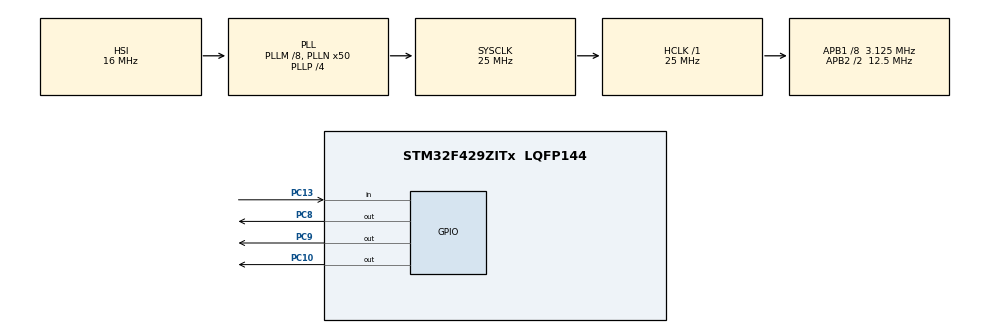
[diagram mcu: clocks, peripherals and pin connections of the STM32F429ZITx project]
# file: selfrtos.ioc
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FREERTOS.BinarySemaphores01=myBinarySem01,Dynamic,NULL
FREERTOS.Tasks01=defaultTask,0,128,StartDefaultTask,Default,NULL,Dynamic,NULL,NULL;shayantask,-3,128,startshayntask,Default,NULL,Dynamic,NULL,NULL
Mcu.Family=STM32F4
Mcu.Name=STM32F429ZITx
Mcu.Package=LQFP144
NVIC.PriorityGroup=NVIC_PRIORITYGROUP_4
NVIC.RCC_IRQn=true\:5\:0\:false\:false\:true\:true\:true
NVIC.TIM6_DAC_IRQn=true\:0\:0\:false\:false\:true\:false\:false
NVIC.TimeBase=TIM6_DAC_IRQn
NVIC.TimeBaseIP=TIM6
PC10.Signal=GPIO_Output
PC13.Signal=GPIO_Input
PC8.Signal=GPIO_Output
PC9.Signal=GPIO_Output
ProjectManager.HeapSize=0x200
ProjectManager.StackSize=0x400
ProjectManager.TargetToolchain=SW4STM32
RCC.48MHZClocksFreq_Value=14285714.285714285
RCC.AHBFreq_Value=25000000
RCC.APB1CLKDivider=RCC_HCLK_DIV8
RCC.APB1Freq_Value=3125000
RCC.APB1TimFreq_Value=6250000
RCC.APB2CLKDivider=RCC_HCLK_DIV2
RCC.APB2Freq_Value=12500000
RCC.APB2TimCLKDivider=1
RCC.APB2TimFreq_Value=12500000
RCC.CortexFreq_Value=25000000
RCC.HCLKFreq_Value=25000000
RCC.HSE_VALUE=8000000
RCC.HSI_VALUE=16000000
RCC.LSE_VALUE=32768
RCC.PLLM=8
RCC.PLLMUL=RCC_PLL_MUL9
RCC.PLLN=50
RCC.PLLP=RCC_PLLP_DIV4
RCC.PLLQ=7
RCC.PRESCALERUSB=RCC_USBCLKSOURCE_PLL_DIV1_5
RCC.SYSCLKFreq_VALUE=25000000
RCC.SYSCLKSource=RCC_SYSCLKSOURCE_PLLCLK
RCC.SYSCLKSourceVirtual=RCC_SYSCLKSOURCE_PLLCLK
RCC.USBFreq_Value=48000000
RCC.VCOOutputFreq_Value=100000000
VP_FREERTOS_VS_ENABLE.Mode=Enabled
VP_SYS_VS_tim6.Mode=TIM6
board=NUCLEO-F429ZI

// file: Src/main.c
/**
  ******************************************************************************
  * @file           : main.c
  * @brief          : Main program body
  ******************************************************************************
  * This notice applies to any and all portions of this file
  * that are not between comment pairs USER CODE BEGIN and
  * USER CODE END. Other portions of this file, whether
  * inserted by the user or by software development tools
  * are owned by their respective copyright owners.
  *
  * Copyright (c) 2019 STMicroelectronics International N.V.
  * All rights reserved.
  *
  * Redistribution and use in source and binary forms, with or without
  * modification, are permitted, provided that the following conditions are met:
  *
  * 1. Redistribution of source code must retain the above copyright notice,
  *    this list of conditions and the following disclaimer.
  * 2. Redistributions in binary form must reproduce the above copyright notice,
  *    this list of conditions and the following disclaimer in the documentation
  *    and/or other materials provided with the distribution.
  * 3. Neither the name of STMicroelectronics nor the names of other
  *    contributors to this software may be used to endorse or promote products
  *    derived from this software without specific written permission.
  * 4. This software, including modifications and/or derivative works of this
  *    software, must execute solely and exclusively on microcontroller or
  *    microprocessor devices manufactured by or for STMicroelectronics.
  * 5. Redistribution and use of this software other than as permitted under
  *    this license is void and will automatically terminate your rights under
  *    this license.
  *
  * THIS SOFTWARE IS PROVIDED BY STMICROELECTRONICS AND CONTRIBUTORS "AS IS"
  * AND ANY EXPRESS, IMPLIED OR STATUTORY WARRANTIES, INCLUDING, BUT NOT
  * LIMITED TO, THE IMPLIED WARRANTIES OF MERCHANTABILITY, FITNESS FOR A
  * PARTICULAR PURPOSE AND NON-INFRINGEMENT OF THIRD PARTY INTELLECTUAL PROPERTY
  * RIGHTS ARE DISCLAIMED TO THE FULLEST EXTENT PERMITTED BY LAW. IN NO EVENT
  * SHALL STMICROELECTRONICS OR CONTRIBUTORS BE LIABLE FOR ANY DIRECT, INDIRECT,
  * INCIDENTAL, SPECIAL, EXEMPLARY, OR CONSEQUENTIAL DAMAGES (INCLUDING, BUT NOT
  * LIMITED TO, PROCUREMENT OF SUBSTITUTE GOODS OR SERVICES; LOSS OF USE, DATA,
  * OR PROFITS; OR BUSINESS INTERRUPTION) HOWEVER CAUSED AND ON ANY THEORY OF
  * LIABILITY, WHETHER IN CONTRACT, STRICT LIABILITY, OR TORT (INCLUDING
  * NEGLIGENCE OR OTHERWISE) ARISING IN ANY WAY OUT OF THE USE OF THIS SOFTWARE,
  * EVEN IF ADVISED OF THE POSSIBILITY OF SUCH DAMAGE.
  *
  ******************************************************************************
  */
#include "main.h"
#include "stm32f4xx_hal.h"
#include "cmsis_os.h"
#include "UARTinit.h"

osThreadId defaultTaskHandle;
osThreadId shayantaskHandle;
osSemaphoreId myBinarySem01Handle;

/* USER CODE BEGIN PV */
/* Private variables ---------------------------------------------------------*/

/* USER CODE END PV */

void SystemClock_Config(void);
static void MX_GPIO_Init(void);
void StartDefaultTask(void const * argument);
void startshayntask(void const * argument);
//void Setuart(UART_HandleTypeDef *huart);
/* USER CODE BEGIN PFP */
/* Private function prototypes -----------------------------------------------*/

/* USER CODE END PFP */

/* USER CODE BEGIN 0 */

/* UART handler declaration */
UART_HandleTypeDef UartHandle;
uint8_t mydata[13] = "sosyanworld\r\n";

/* USER CODE END 0 */

int main(void)
{

  /* MCU Configuration----------------------------------------------------------*/

  /* Reset of all peripherals, Initializes the Flash interface and the Systick. */
  HAL_Init();

  /* Configure the system clock */
  SystemClock_Config();

  /* Initialize all configured peripherals */
  MX_GPIO_Init();
  /* USER CODE BEGIN 2 */
  Setuart(&UartHandle);

  /*
	  __HAL_RCC_USART3_CLK_ENABLE();

	  UartHandle.Instance        = USARTx;
	  UartHandle.Init.BaudRate   = 9600;
	  UartHandle.Init.WordLength = UART_WORDLENGTH_8B;
	  UartHandle.Init.StopBits   = UART_STOPBITS_1;
	  UartHandle.Init.Parity     = UART_PARITY_ODD;
	  UartHandle.Init.HwFlowCtl  = UART_HWCONTROL_NONE;
	  UartHandle.Init.Mode       = UART_MODE_TX_RX;
	  UartHandle.Init.OverSampling = UART_OVERSAMPLING_16;

	  */

  if (HAL_UART_Init(&UartHandle) != HAL_OK)
  {
    /* Initialization Error */
    Error_Handler();
  }
  /* Output a message on Hyperterminal using printf function */
  	    HAL_UART_Transmit(&UartHandle,mydata,13,10);
  /* USER CODE END 2 */

  /* Create the semaphores(s) */
  /* definition and creation of myBinarySem01 */
  osSemaphoreDef(myBinarySem01);
  myBinarySem01Handle = osSemaphoreCreate(osSemaphore(myBinarySem01), 1);

  /* Create the thread(s) */
  /* definition and creation of defaultTask */
  osThreadDef(defaultTask, StartDefaultTask, osPriorityNormal, 0, 128);
  defaultTaskHandle = osThreadCreate(osThread(defaultTask), NULL);

  /* definition and creation of shayantask */
  osThreadDef(shayantask, startshayntask, osPriorityIdle, 0, 128);
  shayantaskHandle = osThreadCreate(osThread(shayantask), NULL);

  /* Start scheduler */
  osKernelStart();

  /* We should never get here as control is now taken by the scheduler */

  /* Infinite loop */
  while (1)
  {

  }

}

void SystemClock_Config(void)
{

  RCC_OscInitTypeDef RCC_OscInitStruct;
  RCC_ClkInitTypeDef RCC_ClkInitStruct;

    /**Configure the main internal regulator output voltage
    */
  __HAL_RCC_PWR_CLK_ENABLE();

  __HAL_PWR_VOLTAGESCALING_CONFIG(PWR_REGULATOR_VOLTAGE_SCALE3);

    /**Initializes the CPU, AHB and APB busses clocks
    */
  RCC_OscInitStruct.OscillatorType = RCC_OSCILLATORTYPE_HSI;
  RCC_OscInitStruct.HSIState = RCC_HSI_ON;
  RCC_OscInitStruct.HSICalibrationValue = 16;
  RCC_OscInitStruct.PLL.PLLState = RCC_PLL_ON;
  RCC_OscInitStruct.PLL.PLLSource = RCC_PLLSOURCE_HSI;
  RCC_OscInitStruct.PLL.PLLM = 8;
  RCC_OscInitStruct.PLL.PLLN = 50;
  RCC_OscInitStruct.PLL.PLLP = RCC_PLLP_DIV4;
  RCC_OscInitStruct.PLL.PLLQ = 7;
  if (HAL_RCC_OscConfig(&RCC_OscInitStruct) != HAL_OK)
  {
    _Error_Handler(__FILE__, __LINE__);
  }

    /**Initializes the CPU, AHB and APB busses clocks
    */
  RCC_ClkInitStruct.ClockType = RCC_CLOCKTYPE_HCLK|RCC_CLOCKTYPE_SYSCLK
                              |RCC_CLOCKTYPE_PCLK1|RCC_CLOCKTYPE_PCLK2;
  RCC_ClkInitStruct.SYSCLKSource = RCC_SYSCLKSOURCE_PLLCLK;
  RCC_ClkInitStruct.AHBCLKDivider = RCC_SYSCLK_DIV1;
  RCC_ClkInitStruct.APB1CLKDivider = RCC_HCLK_DIV8;
  RCC_ClkInitStruct.APB2CLKDivider = RCC_HCLK_DIV2;

  if (HAL_RCC_ClockConfig(&RCC_ClkInitStruct, FLASH_LATENCY_0) != HAL_OK)
  {
    _Error_Handler(__FILE__, __LINE__);
  }

    /**Configure the Systick interrupt time
    */
  HAL_SYSTICK_Config(HAL_RCC_GetHCLKFreq()/1000);

    /**Configure the Systick
    */
  HAL_SYSTICK_CLKSourceConfig(SYSTICK_CLKSOURCE_HCLK);

  /* SysTick_IRQn interrupt configuration */
  HAL_NVIC_SetPriority(SysTick_IRQn, 15, 0);
}

/** Configure pins as
        * Analog
        * Input
        * Output
        * EVENT_OUT
        * EXTI
*/
static void MX_GPIO_Init(void)
{
	 GPIO_InitTypeDef GPIO_InitStruct;

	  /* GPIO Ports Clock Enable */
	  __HAL_RCC_GPIOC_CLK_ENABLE();
	  __HAL_RCC_GPIOH_CLK_ENABLE();

	  /*Configure GPIO pin Output Level */
	  HAL_GPIO_WritePin(GPIOC, GPIO_PIN_9|GPIO_PIN_10, GPIO_PIN_SET);

	  /*Configure GPIO pins : PC8 PC9 PC10 */
	  GPIO_InitStruct.Pin = GPIO_PIN_9|GPIO_PIN_10;
	  GPIO_InitStruct.Mode = GPIO_MODE_OUTPUT_PP;
	  GPIO_InitStruct.Pull = GPIO_NOPULL;
	  GPIO_InitStruct.Speed = GPIO_SPEED_FREQ_LOW;
	  HAL_GPIO_Init(GPIOC, &GPIO_InitStruct);

	  GPIO_InitStruct.Pin   = GPIO_PIN_13;
	  GPIO_InitStruct.Mode  = GPIO_MODE_INPUT;
	  GPIO_InitStruct.Pull  = GPIO_NOPULL;
	  GPIO_InitStruct.Speed = GPIO_SPEED_FAST;
	  HAL_GPIO_Init(GPIOC, &GPIO_InitStruct);

}

/* StartDefaultTask function */
void StartDefaultTask(void const * argument)
{

  /* USER CODE BEGIN 5 */
  /* Infinite loop */
  for(;;)
  {

	  if (HAL_GPIO_ReadPin(GPIOC, GPIO_PIN_13))
	  {
	 	HAL_GPIO_WritePin(GPIOC, GPIO_PIN_10, GPIO_PIN_SET);
	 	HAL_UART_Transmit(&UartHandle,mydata,13,10);
	  }
	  else
	  {
	 	 HAL_GPIO_WritePin(GPIOC, GPIO_PIN_10, GPIO_PIN_RESET);
	  }
    osDelay(1);
  }
  /* USER CODE END 5 */
}

/* startshayntask function */
void startshayntask(void const * argument)
{
  for(;;)
  {
    osDelay(1);
  }
}

void HAL_TIM_PeriodElapsedCallback(TIM_HandleTypeDef *htim)
{
  if (htim->Instance == TIM6) {
    HAL_IncTick();
  }
}

void _Error_Handler(char *file, int line)
{
  while(1)
  {
  }
}

/************************ (C) COPYRIGHT STMicroelectronics *****END OF FILE****/
